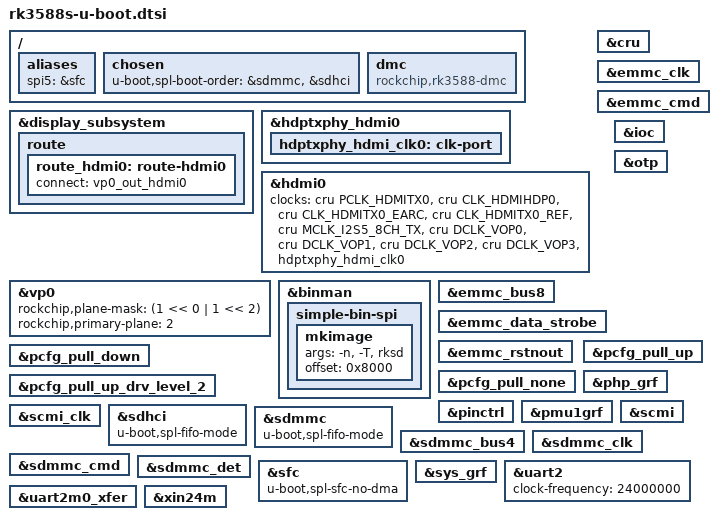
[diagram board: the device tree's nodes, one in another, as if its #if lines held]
// SPDX-License-Identifier: (GPL-2.0+ OR MIT)
/*
* Copyright (c) 2022 Edgeble AI Technologies Pvt. Ltd.
*/

#include "rockchip-u-boot.dtsi"

/ {
	aliases {
		spi5 = &sfc;
	};
	
	chosen {
		u-boot,spl-boot-order = &sdmmc, &sdhci;
	};
	
	dmc {
		compatible = "rockchip,rk3588-dmc";
		bootph-all;
	};
};

#ifdef CONFIG_DRM_ROCKCHIP
#include <dt-bindings/clock/rockchip,rk3588-cru.h>
&display_subsystem {
	bootph-all;
	
	route {
		route_hdmi0: route-hdmi0 {
			connect = <&vp0_out_hdmi0>;
		};
	};
};

&hdptxphy_hdmi0 {
	hdptxphy_hdmi_clk0: clk-port {
		#clock-cells = <0>;
		status = "okay";
	};
};

&hdmi0 {
	clocks = <&cru PCLK_HDMITX0>,
	<&cru CLK_HDMIHDP0>,
	<&cru CLK_HDMITX0_EARC>,
	<&cru CLK_HDMITX0_REF>,
	<&cru MCLK_I2S5_8CH_TX>,
	<&cru DCLK_VOP0>,
	<&cru DCLK_VOP1>,
	<&cru DCLK_VOP2>,
	<&cru DCLK_VOP3>,
	<&hdptxphy_hdmi_clk0>;
	clock-names = "pclk",
	"hpd",
	"earc",
	"hdmitx_ref",
	"aud",
	"dclk_vp0",
	"dclk_vp1",
	"dclk_vp2",
	"dclk_vp3",
	"link_clk";
};

&vp0 {
	rockchip,plane-mask = <(1 << 0 | 1 << 2)>;
	rockchip,primary-plane = <2>;
};
#endif

#ifdef CONFIG_ROCKCHIP_SPI_IMAGE
&binman {
	simple-bin-spi {
		mkimage {
			args = "-n", CONFIG_SYS_SOC, "-T", "rksd";
			offset = <0x8000>;
		};
	};
};
#endif

&cru {
	bootph-all;
};

&emmc_bus8 {
	bootph-pre-ram;
	bootph-some-ram;
};

&emmc_clk {
	bootph-pre-ram;
	bootph-some-ram;
};

&emmc_cmd {
	bootph-pre-ram;
	bootph-some-ram;
};

&emmc_data_strobe {
	bootph-pre-ram;
	bootph-some-ram;
};

&emmc_rstnout {
	bootph-pre-ram;
	bootph-some-ram;
};

&ioc {
	bootph-all;
};

&otp {
	bootph-some-ram;
};

&pcfg_pull_down {
	bootph-all;
};

&pcfg_pull_none {
	bootph-all;
};

&pcfg_pull_up {
	bootph-all;
};

&pcfg_pull_up_drv_level_2 {
	bootph-pre-ram;
	bootph-some-ram;
};

&php_grf {
	bootph-all;
};

&pinctrl {
	bootph-all;
};

&pmu1grf {
	bootph-all;
};

&scmi {
	bootph-pre-ram;
	bootph-some-ram;
};

&scmi_clk {
	bootph-pre-ram;
	bootph-some-ram;
};

&sdhci {
	bootph-pre-ram;
	bootph-some-ram;
	u-boot,spl-fifo-mode;
};

&sdmmc {
	bootph-pre-ram;
	bootph-some-ram;
	u-boot,spl-fifo-mode;
};

&sdmmc_bus4 {
	bootph-pre-ram;
	bootph-some-ram;
};

&sdmmc_clk {
	bootph-pre-ram;
	bootph-some-ram;
};

&sdmmc_cmd {
	bootph-pre-ram;
	bootph-some-ram;
};

&sdmmc_det {
	bootph-pre-ram;
	bootph-some-ram;
};

&sfc {
	u-boot,spl-sfc-no-dma;
};

&sys_grf {
	bootph-all;
};

&uart2 {
	bootph-all;
	clock-frequency = <24000000>;
};

&uart2m0_xfer {
	bootph-all;
};

&xin24m {
	bootph-all;
};
